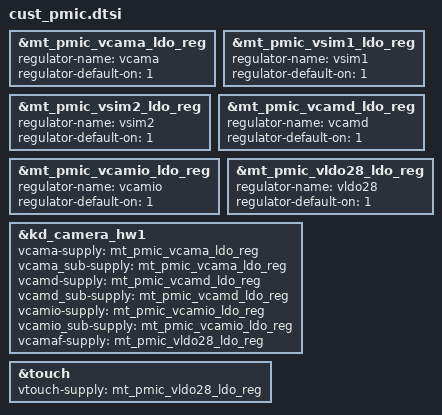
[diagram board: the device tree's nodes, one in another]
/*
 * Generated by MTK SP DrvGen Version: 3.5.160809 for MT6739.
 * 2019-11-11 10:46:44
 * Do Not Modify The File.
 * Copyright Mediatek Inc. (c) 2016.
*/

/*************************
 * PMIC DTSI File
*************************/

&mt_pmic_vcama_ldo_reg {
	regulator-name = "vcama";
	regulator-default-on = <1>; /* 0:skip, 1: off, 2:on */
	status = "okay";
};
&mt_pmic_vsim1_ldo_reg {
	regulator-name = "vsim1";
	regulator-default-on = <1>; /* 0:skip, 1: off, 2:on */
	status = "okay";
};
&mt_pmic_vsim2_ldo_reg {
	regulator-name = "vsim2";
	regulator-default-on = <1>; /* 0:skip, 1: off, 2:on */
	status = "okay";
};
&mt_pmic_vcamd_ldo_reg {
	regulator-name = "vcamd";
	regulator-default-on = <1>; /* 0:skip, 1: off, 2:on */
	status = "okay";
};
&mt_pmic_vcamio_ldo_reg {
	regulator-name = "vcamio";
	regulator-default-on = <1>; /* 0:skip, 1: off, 2:on */
	status = "okay";
};
&mt_pmic_vldo28_ldo_reg {
	regulator-name = "vldo28";
	regulator-default-on = <1>; /* 0:skip, 1: off, 2:on */
	status = "okay";
};

&kd_camera_hw1 {
	vcama-supply = <&mt_pmic_vcama_ldo_reg>;
	vcama_sub-supply = <&mt_pmic_vcama_ldo_reg>;
	vcamd-supply = <&mt_pmic_vcamd_ldo_reg>;
	vcamd_sub-supply = <&mt_pmic_vcamd_ldo_reg>;
	vcamio-supply = <&mt_pmic_vcamio_ldo_reg>;
	vcamio_sub-supply = <&mt_pmic_vcamio_ldo_reg>;
	vcamaf-supply = <&mt_pmic_vldo28_ldo_reg>;
	status = "okay";
};

&touch {
	vtouch-supply = <&mt_pmic_vldo28_ldo_reg>;
	status = "okay";
};
